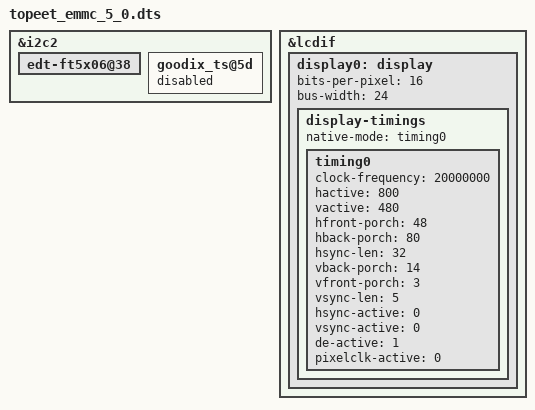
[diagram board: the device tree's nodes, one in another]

#include "imx6ull-14x14-evk-emmc.dts"

&i2c2 {
	edt-ft5x06@38 {
		status = "okay";
	};

	goodix_ts@5d {
		status = "disabled";
	};
};

&lcdif {
	display0: display {
		bits-per-pixel = <16>;
		bus-width = <24>;

		display-timings {
			native-mode = <&timing0>;
			timing0: timing0 {
			clock-frequency = <20000000>;
			hactive = <800>;
			vactive = <480>;
			hfront-porch = <48>;
			hback-porch = <80>;
			hsync-len = <32>;
			vback-porch = <14>;
			vfront-porch = <3>;
			vsync-len = <5>;

			hsync-active = <0>;
			vsync-active = <0>;
			de-active = <1>;
			pixelclk-active = <0>;
			};
		};
	};
};
